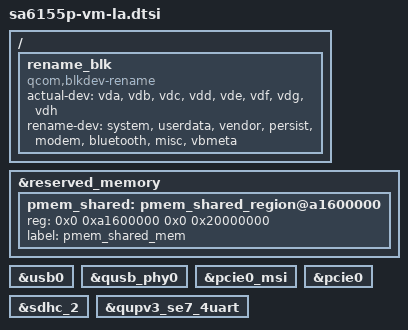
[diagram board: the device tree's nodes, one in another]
&reserved_memory {
	pmem_shared: pmem_shared_region@a1600000 {
		reg = <0x0 0xa1600000 0x0 0x20000000>;
		label = "pmem_shared_mem";
	};
};

/ {
	rename_blk: rename_blk {
		compatible = "qcom,blkdev-rename";
		actual-dev = "vda", "vdb", "vdc",
				"vdd", "vde", "vdf",
				"vdg", "vdh";
		rename-dev = "system", "userdata", "vendor",
				"persist", "modem", "bluetooth",
				"misc", "vbmeta";
	};

};

&usb0 {
	status = "ok";
};

&qusb_phy0 {
	status = "ok";
};

&pcie0_msi {
	status = "ok";
};

&pcie0 {
	status = "ok";
};

&sdhc_2 {
	status = "ok";
};

&qupv3_se7_4uart {
	status = "ok";
};
